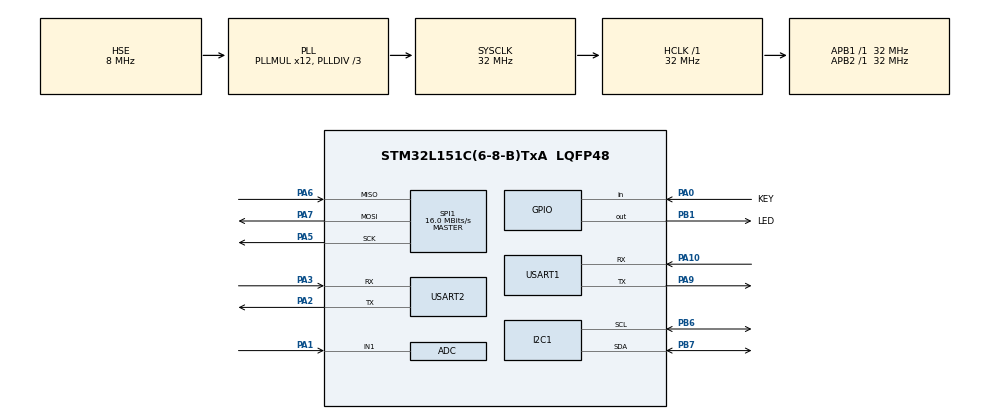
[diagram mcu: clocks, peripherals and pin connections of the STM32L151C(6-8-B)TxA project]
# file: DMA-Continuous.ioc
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ADC.Channel-0\#ChannelRegularConversion=ADC_CHANNEL_1
ADC.ClockPrescaler=ADC_CLOCK_ASYNC_DIV2
ADC.ContinuousConvMode=ENABLE
ADC.DMAContinuousRequests=ENABLE
ADC.DataAlign=ADC_DATAALIGN_RIGHT
ADC.DiscontinuousConvMode=DISABLE
ADC.EOCSelection=EOC_SINGLE_CONV
ADC.EnableAnalogWatchDog=false
ADC.ExternalTrigConvEdge=ADC_EXTERNALTRIGCONVEDGE_NONE
ADC.InjNumberOfConversion=0
ADC.LowPowerAutoPowerOff=ADC_AUTOPOWEROFF_DISABLE
ADC.LowPowerAutoWait=ADC_AUTOWAIT_DISABLE
ADC.NbrOfConversion=1
ADC.NbrOfConversionFlag=1
ADC.Rank-0\#ChannelRegularConversion=1
ADC.Resolution=ADC_RESOLUTION12b
ADC.SamplingTime-0\#ChannelRegularConversion=ADC_SAMPLETIME_4CYCLES
ADC.ScanConvMode=ADC_SCAN_DISABLE
Dma.ADC.0.Direction=DMA_PERIPH_TO_MEMORY
Dma.ADC.0.Instance=DMA1_Channel1
Dma.ADC.0.MemDataAlignment=DMA_MDATAALIGN_HALFWORD
Dma.ADC.0.MemInc=DMA_MINC_ENABLE
Dma.ADC.0.Mode=DMA_CIRCULAR
Dma.ADC.0.PeriphDataAlignment=DMA_PDATAALIGN_HALFWORD
Dma.ADC.0.PeriphInc=DMA_PINC_DISABLE
Dma.ADC.0.Priority=DMA_PRIORITY_LOW
Dma.Request0=ADC
Mcu.Family=STM32L1
Mcu.Name=STM32L151C(6-8-B)TxA
Mcu.Package=LQFP48
NVIC.DMA1_Channel1_IRQn=true\:0\:0\:false
NVIC.PriorityGroup=NVIC_PRIORITYGROUP_4
PA0-WKUP1.GPIO_Label=KEY
PA0-WKUP1.Signal=GPIO_Input
PA1.Mode=IN1
PA1.Signal=ADC_IN1
PA10.Mode=Asynchronous
PA10.Signal=USART1_RX
PA13.Mode=Serial-Wire
PA13.Signal=SYS_JTMS-SWDIO
PA14.Mode=Serial-Wire
PA14.Signal=SYS_JTCK-SWCLK
PA2.Mode=Asynchronous
PA2.Signal=USART2_TX
PA3.Mode=Asynchronous
PA3.Signal=USART2_RX
PA5.Mode=Full_Duplex_Master
PA5.Signal=SPI1_SCK
PA6.Mode=Full_Duplex_Master
PA6.Signal=SPI1_MISO
PA7.Mode=Full_Duplex_Master
PA7.Signal=SPI1_MOSI
PA9.Mode=Asynchronous
PA9.Signal=USART1_TX
PB1.GPIO_Label=LED
PB1.GPIO_PuPd=GPIO_PULLUP
PB1.Signal=GPIO_Output
PB6.Mode=I2C
PB6.Signal=I2C1_SCL
PB7.Mode=I2C
PB7.Signal=I2C1_SDA
PC14-OSC32_IN.Mode=LSE-External-Oscillator
PC14-OSC32_IN.Signal=RCC_OSC32_IN
PC15-OSC32_OUT.Mode=LSE-External-Oscillator
PC15-OSC32_OUT.Signal=RCC_OSC32_OUT
PH0-OSC_IN.Mode=HSE-External-Oscillator
PH0-OSC_IN.Signal=RCC_OSC_IN
PH1-OSC_OUT.Mode=HSE-External-Oscillator
PH1-OSC_OUT.Signal=RCC_OSC_OUT
ProjectManager.HeapSize=0x400
ProjectManager.StackSize=0x200
ProjectManager.TargetToolchain=MDK-ARM V5
RCC.AHBFreq_Value=32000000
RCC.APB1Freq_Value=32000000
RCC.APB1TimFreq_Value=32000000
RCC.APB2Freq_Value=32000000
RCC.APB2TimFreq_Value=32000000
RCC.HCLKFreq_Value=32000000
RCC.HSE_VALUE=8000000
RCC.HSI_VALUE=16000000
RCC.MSIClockRange=RCC_MSIRANGE_6
RCC.MSI_VALUE=4194000
RCC.PLLDIV=RCC_PLL_DIV3
RCC.PLLMUL=RCC_PLL_MUL12
RCC.PLLSourceVirtual=RCC_PLLSOURCE_HSE
RCC.RTCClockSelection=RCC_RTCCLKSOURCE_LSI
RCC.RTCClockSelectionVirtual=RCC_RTCCLKSOURCE_LSI
RCC.SYSCLKFreq_VALUE=32000000
RCC.SYSCLKSource=RCC_SYSCLKSOURCE_PLLCLK
RCC.USBOutput=48000000
RCC.VCOOutputFreq_Value=96000000
SPI1.BaudRatePrescaler=SPI_BAUDRATEPRESCALER_2
SPI1.CalculateBaudRate=16.0 MBits/s
SPI1.Mode=SPI_MODE_MASTER
board=DMA-Continuous

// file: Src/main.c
/**
******************************************************************************
* File Name          : main.c
* Description        : Main program body
******************************************************************************
*
* COPYRIGHT(c) 2015 STMicroelectronics
*
* Redistribution and use in source and binary forms, with or without modification,
* are permitted provided that the following conditions are met:
*   1. Redistributions of source code must retain the above copyright notice,
*      this list of conditions and the following disclaimer.
*   2. Redistributions in binary form must reproduce the above copyright notice,
*      this list of conditions and the following disclaimer in the documentation
*      and/or other materials provided with the distribution.
*   3. Neither the name of STMicroelectronics nor the names of its contributors
*      may be used to endorse or promote products derived from this software
*      without specific prior written permission.
*
* THIS SOFTWARE IS PROVIDED BY THE COPYRIGHT HOLDERS AND CONTRIBUTORS "AS IS"
* AND ANY EXPRESS OR IMPLIED WARRANTIES, INCLUDING, BUT NOT LIMITED TO, THE
* IMPLIED WARRANTIES OF MERCHANTABILITY AND FITNESS FOR A PARTICULAR PURPOSE ARE
* DISCLAIMED. IN NO EVENT SHALL THE COPYRIGHT HOLDER OR CONTRIBUTORS BE LIABLE
* FOR ANY DIRECT, INDIRECT, INCIDENTAL, SPECIAL, EXEMPLARY, OR CONSEQUENTIAL
* DAMAGES (INCLUDING, BUT NOT LIMITED TO, PROCUREMENT OF SUBSTITUTE GOODS OR
* SERVICES; LOSS OF USE, DATA, OR PROFITS; OR BUSINESS INTERRUPTION) HOWEVER
* CAUSED AND ON ANY THEORY OF LIABILITY, WHETHER IN CONTRACT, STRICT LIABILITY,
* OR TORT (INCLUDING NEGLIGENCE OR OTHERWISE) ARISING IN ANY WAY OUT OF THE USE
* OF THIS SOFTWARE, EVEN IF ADVISED OF THE POSSIBILITY OF SUCH DAMAGE.
*
******************************************************************************
*/
#include "stm32l1xx_hal.h"
#include "adc.h"
#include "dma.h"
#include "i2c.h"
#include "spi.h"
#include "usart.h"
#include "gpio.h"

/* USER CODE BEGIN PV */
/* Private variables ---------------------------------------------------------*/

/* USER CODE END PV */

void SystemClock_Config(void);

/* USER CODE BEGIN PFP */
/* Private function prototypes -----------------------------------------------*/

/* USER CODE END PFP */

/* USER CODE BEGIN 0 */
/* Variable used to get converted value */
// 采样10个
__IO uint16_t uhADCxConvertedValue[10]={0};
/* USER CODE END 0 */

int main(void)
{

	/* MCU Configuration----------------------------------------------------------*/

	/* Reset of all peripherals, Initializes the Flash interface and the Systick. */
	HAL_Init();

	/* Configure the system clock */
	SystemClock_Config();

	/* Initialize all configured peripherals */
	MX_GPIO_Init();
	MX_DMA_Init();
	MX_ADC_Init();
	MX_I2C1_Init();
	MX_SPI1_Init();
	MX_USART1_UART_Init();
	MX_USART2_UART_Init();

	/* USER CODE BEGIN 2 */
	// 启动DMA连续ADC转换前，请先禁用MX_DMA_Init()内的DMA中断，否则会阻塞其他代码执行
	// 存放ADC数值的内存地址，入口参数虽然是32bit，但DMA存放的时候按照DMA设置的数据宽度进行递增
	// 采样10次
	HAL_ADC_Start_DMA(&hadc, (uint32_t*)uhADCxConvertedValue, 10);

	// 采样1次
	// HAL_ADC_Start_DMA(&hadc, (uint32_t*)&uhADCxConvertedValue[0], 1);
	/* USER CODE END 2 */

	/* Infinite loop */
	/* USER CODE BEGIN WHILE */
	while (1)
	{
		HAL_Delay(100);
		printf("adc:");
		uint8_t i;
		for(i=0;i<10;i++)
			printf("%d,\t",uhADCxConvertedValue[i]);
		printf("\r\n");
		/* USER CODE END WHILE */

	}

}

/** System Clock Configuration
*/
void SystemClock_Config(void)
{

	RCC_OscInitTypeDef RCC_OscInitStruct;
	RCC_ClkInitTypeDef RCC_ClkInitStruct;
	RCC_PeriphCLKInitTypeDef PeriphClkInit;

	__PWR_CLK_ENABLE();

	__HAL_PWR_VOLTAGESCALING_CONFIG(PWR_REGULATOR_VOLTAGE_SCALE1);

	RCC_OscInitStruct.OscillatorType = RCC_OSCILLATORTYPE_HSI|RCC_OSCILLATORTYPE_LSI
		|RCC_OSCILLATORTYPE_HSE;
	RCC_OscInitStruct.HSEState = RCC_HSE_ON;
	RCC_OscInitStruct.HSIState = RCC_HSI_ON;
	RCC_OscInitStruct.HSICalibrationValue = 16;
	RCC_OscInitStruct.LSIState = RCC_LSI_ON;
	RCC_OscInitStruct.PLL.PLLState = RCC_PLL_ON;
	RCC_OscInitStruct.PLL.PLLSource = RCC_PLLSOURCE_HSE;
	RCC_OscInitStruct.PLL.PLLMUL = RCC_PLL_MUL12;
	RCC_OscInitStruct.PLL.PLLDIV = RCC_PLL_DIV3;
	HAL_RCC_OscConfig(&RCC_OscInitStruct);

	RCC_ClkInitStruct.ClockType = RCC_CLOCKTYPE_SYSCLK;
	RCC_ClkInitStruct.SYSCLKSource = RCC_SYSCLKSOURCE_PLLCLK;
	RCC_ClkInitStruct.AHBCLKDivider = RCC_SYSCLK_DIV1;
	RCC_ClkInitStruct.APB1CLKDivider = RCC_HCLK_DIV1;
	RCC_ClkInitStruct.APB2CLKDivider = RCC_HCLK_DIV1;
	HAL_RCC_ClockConfig(&RCC_ClkInitStruct, FLASH_LATENCY_1);

	PeriphClkInit.PeriphClockSelection = RCC_PERIPHCLK_RTC;
	PeriphClkInit.RTCClockSelection = RCC_RTCCLKSOURCE_LSI;
	HAL_RCCEx_PeriphCLKConfig(&PeriphClkInit);

	HAL_SYSTICK_Config(HAL_RCC_GetHCLKFreq()/1000);

	HAL_SYSTICK_CLKSourceConfig(SYSTICK_CLKSOURCE_HCLK);

	/* SysTick_IRQn interrupt configuration */
	HAL_NVIC_SetPriority(SysTick_IRQn, 0, 0);
}

/* USER CODE BEGIN 4 */
void HAL_ADC_ConvCpltCallback(ADC_HandleTypeDef* hadc)
{
	printf("ADC CP:%d\r\n",uhADCxConvertedValue);
}
/* USER CODE END 4 */

/************************ (C) COPYRIGHT STMicroelectronics *****END OF FILE****/
